# CH32X315 register map
Vendor: WCH Ltd.; File version: 1.1
Registers are 32-bit, read-write, reset 0x0 unless marked. A register's access mark holds for its fields unless they carry their own. Offsets are from the block's base; [hi:lo] are bit positions; {n}, {i} and the like mark numbered series.

## WWDG — Window watchdog
Base 0x40002C00
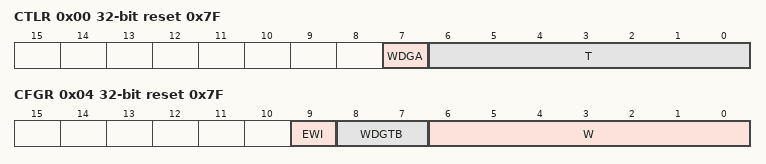
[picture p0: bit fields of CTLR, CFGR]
0x00 CTLR reset 0x7F — Control register (WWDG_CR)
  [7] WDGA — Activation bit
  [6:0] T — 7-bit counter (MSB to LSB)
0x04 CFGR reset 0x7F — Configuration register (WWDG_CFGR)
  [9] EWI — Early Wakeup Interrupt
  [8:7] WDGTB — Timer Base
  [6:0] W — 7-bit window value
0x08 STATR — Status register (WWDG_SR)
  [0] EWIF — Early Wakeup Interrupt Flag

## EXTI
Base 0x40010400
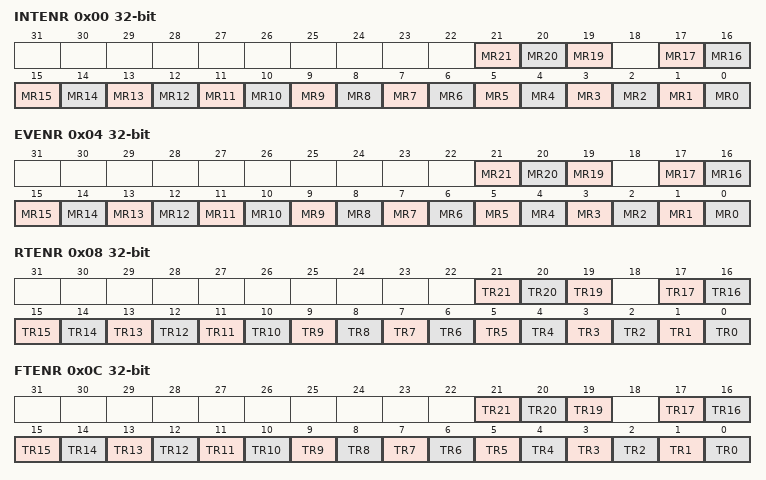
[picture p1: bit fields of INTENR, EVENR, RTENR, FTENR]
0x00 INTENR — Interrupt mask register (EXTI_INTENR)
  [21] MR21 — Interrupt Mask on line 21
  [20] MR20 — Interrupt Mask on line 20
  [19] MR19 — Interrupt Mask on line 19
  [n] MR{n} (n=0..17) — Interrupt Mask on line {n}
0x04 EVENR — Event mask register (EXTI_EVENR)
  [21] MR21 — Event Mask on line 21
  [20] MR20 — Event Mask on line 20
  [19] MR19 — Event Mask on line 19
  [n] MR{n} (n=0..17) — Event Mask on line {n}
0x08 RTENR — Rising Trigger selection register (EXTI_RTENR)
  [21] TR21 — Rising trigger event configuration of line 21
  [20] TR20 — Rising trigger event configuration of line 20
  [19] TR19 — Rising trigger event configuration of line 19
  [n] TR{n} (n=0..17) — Rising trigger event configuration of line {n}
0x0C FTENR — Falling Trigger selection register (EXTI_FTENR)
  [21] TR21 — Falling trigger event configuration of line 21
  [20] TR20 — Falling trigger event configuration of line 20
  [19] TR19 — Falling trigger event configuration of line 19
  [n] TR{n} (n=0..17) — Falling trigger event configuration of line {n}
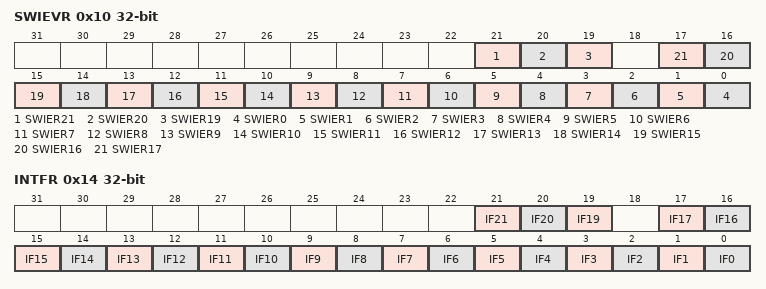
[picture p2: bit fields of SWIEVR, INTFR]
0x10 SWIEVR — Software interrupt event register (EXTI_SWIEVR)
  [21] SWIER21 — Software Interrupt on line 21
  [20] SWIER20 — Software Interrupt on line 20
  [19] SWIER19 — Software Interrupt on line 19
  [n] SWIER{n} (n=0..17) — Software Interrupt on line {n}
0x14 INTFR — interrupt flag register (EXTI_INTFR)
  [21] IF21 — interrupt flag bit 21
  [20] IF20 — interrupt flag bit 20
  [19] IF19 — interrupt flag bit 19
  [n] IF{n} (n=0..17) — interrupt flag bit {n}

## STK — SysTick
Base 0xE000F000
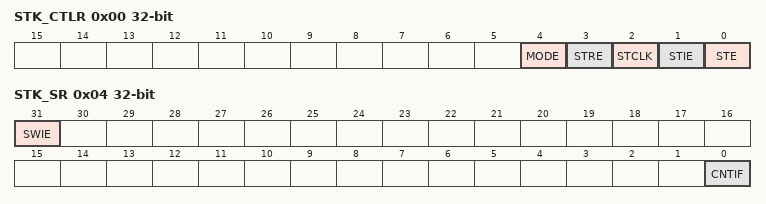
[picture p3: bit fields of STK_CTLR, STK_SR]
0x00 STK_CTLR — System count control register
  [4] MODE — Counting Mode
  [3] STRE — Auto Reload Count Enable Bit
  [2] STCLK — Counter Clock Source Selection Bit
  [1] STIE — Counter interrupt enable control bit
  [0] STE — System counter enable control bit
0x04 STK_SR — System counter interrupt status register
  [31] SWIE — software Interrupt trigger enable
  [0] CNTIF — Systick Interrupt Flag
0x08 STK_CNTL — System counter low bit register
  [31:0] CNT — Systick counter register low 32 bit
0x10 STK_CMPLR — System counter comparison low bit register
  [31:0] CMP — Set the comparison counter value to 32 bits lower : STK interrupts are triggered when the upcount CMP register value is equal to the CNT count value or when the downcount CMP register value is equal to 0

## GPIOA — General purpose I/O
Base 0x40010800
Same registers: GPIOB 0x40010C00, GPIOC 0x40011000, GPIOD 0x40011400
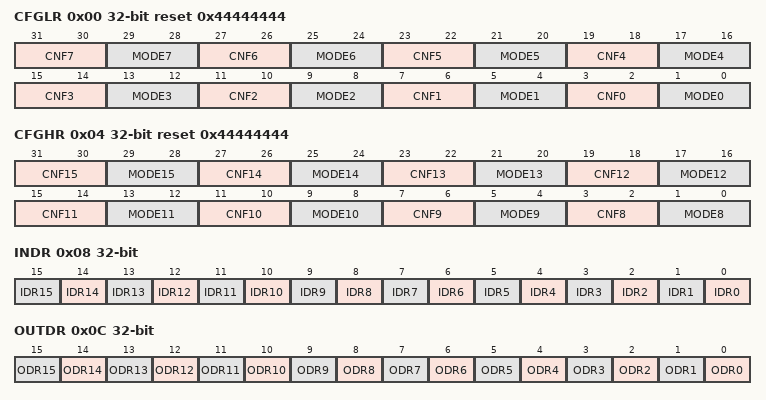
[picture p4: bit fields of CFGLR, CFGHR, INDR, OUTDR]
0x00 CFGLR reset 0x44444444 — Port configuration register low (GPIOn_CFGLR)
  [31:30] CNF7 — Port n.7 configuration bits
  [29:28] MODE7 — Port n.7 mode bits
  [27:26] CNF6 — Port n.6 configuration bits
  [25:24] MODE6 — Port n.6 mode bits
  [23:22] CNF5 — Port n.5 configuration bits
  [21:20] MODE5 — Port n.5 mode bits
  [19:18] CNF4 — Port n.4 configuration bits
  [17:16] MODE4 — Port n.4 mode bits
  [15:14] CNF3 — Port n.3 configuration bits
  [13:12] MODE3 — Port n.3 mode bits
  [11:10] CNF2 — Port n.2 configuration bits
  [9:8] MODE2 — Port n.2 mode bits
  [7:6] CNF1 — Port n.1 configuration bits
  [5:4] MODE1 — Port n.1 mode bits
  [3:2] CNF0 — Port n.0 configuration bits
  [1:0] MODE0 — Port n.0 mode bits
0x04 CFGHR reset 0x44444444 — Port configuration register high (GPIOn_CFGHR)
  [31:30] CNF15 — Port n.15 configuration bits
  [29:28] MODE15 — Port n.15 mode bits
  [27:26] CNF14 — Port n.14 configuration bits
  [25:24] MODE14 — Port n.14 mode bits
  [23:22] CNF13 — Port n.13 configuration bits
  [21:20] MODE13 — Port n.13 mode bits
  [19:18] CNF12 — Port n.12 configuration bits
  [17:16] MODE12 — Port n.12 mode bits
  [15:14] CNF11 — Port n.11 configuration bits
  [13:12] MODE11 — Port n.11 mode bits
  [11:10] CNF10 — Port n.10 configuration bits
  [9:8] MODE10 — Port n.10 mode bits
  [7:6] CNF9 — Port n.9 configuration bits
  [5:4] MODE9 — Port n.9 mode bits
  [3:2] CNF8 — Port n.8 configuration bits
  [1:0] MODE8 — Port n.8 mode bits
0x08 INDR ro — Port input data register (GPIOn_INDR)
  [n] IDR{n} (n=0..15) — Port input data
0x0C OUTDR — Port output data register (GPIOn_OUTDR)
  [n] ODR{n} (n=0..15) — Port output data
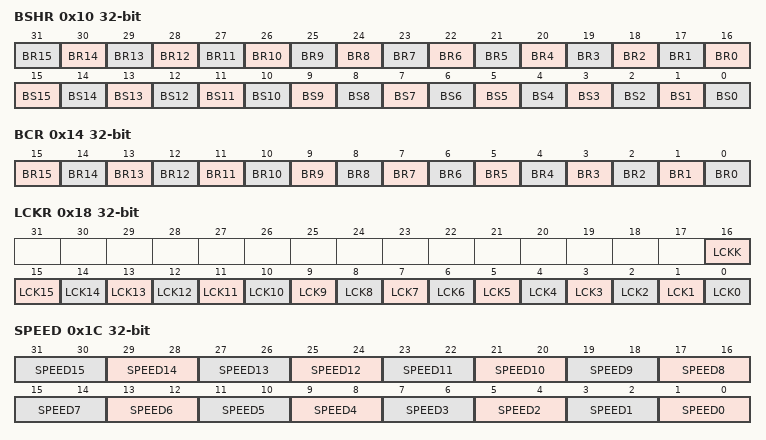
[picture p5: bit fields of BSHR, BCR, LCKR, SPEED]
0x10 BSHR wo — Port bit set/reset register (GPIOn_BSHR)
  [n+16] BR{n} (n=0..15) — Reset bit {n}
  [n] BS{n} (n=3..15) — Set bit {n}
  [2] BS2 — Set bit 1
  [1] BS1 — Set bit 1
  [0] BS0 — Set bit 0
0x14 BCR wo — Port bit reset register (GPIOn_BCR)
  [n] BR{n} (n=3..15) — Reset bit {n}
  [2] BR2 — Reset bit 1
  [1] BR1 — Reset bit 1
  [0] BR0 — Reset bit 0
0x18 LCKR — Port configuration lock register
  [16] LCKK — Lock key
  [n] LCK{n} (n=0..15) — Port A Lock bit {n}
0x1C SPEED — Port speed register
  [2n+1:2n] SPEED{n} (n=0..15) — Port A speed bit {n}
